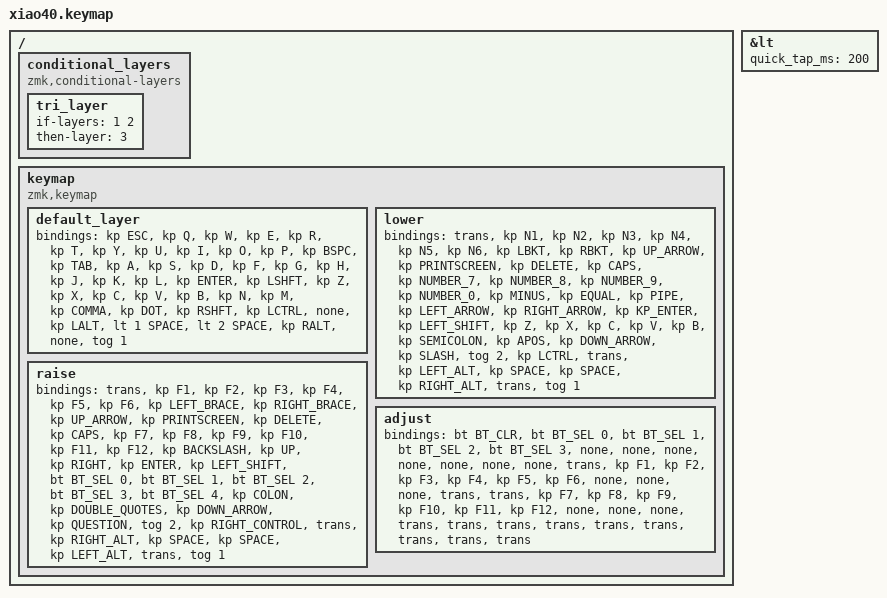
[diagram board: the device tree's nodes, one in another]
/*
 * Copyright (c) 2022 Ramon Imbao
 *
 * SPDX-License-Identifier: MIT
 */

#include <behaviors.dtsi>
#include <dt-bindings/zmk/keys.h>
#include <dt-bindings/zmk/bt.h>// Using layer taps on thumbs, having quick tap as well helps w/ repeating space/backspace
&lt {
    quick_tap_ms = <200>;
};

/ {
    conditional_layers {
        compatible = "zmk,conditional-layers";

        tri_layer {
            if-layers = <1 2>;
            then-layer = <3>;
        };
    };

    keymap {
        compatible = "zmk,keymap";

        default_layer {
            bindings = <
 &kp ESC   &kp Q   &kp W   &kp E   &kp R   &kp T   &kp Y   &kp U   &kp I   &kp O   &kp P  &kp BSPC  &kp TAB   &kp A   &kp S   &kp D   &kp F   &kp G   &kp H   &kp J   &kp K   &kp L  &kp ENTER  &kp LSHFT   &kp Z   &kp X   &kp C   &kp V   &kp B   &kp N   &kp M  &kp COMMA  &kp DOT  &kp RSHFT  &kp LCTRL   &none  &kp LALT  &lt 1 SPACE  &lt 2 SPACE  &kp RALT   &none  &tog 1
            >;
        };

        lower {
            bindings = <
 &trans  &kp N1  &kp N2  &kp N3  &kp N4  &kp N5  &kp N6  &kp LBKT  &kp RBKT  &kp UP_ARROW  &kp PRINTSCREEN  &kp DELETE  &kp CAPS  &kp NUMBER_7  &kp NUMBER_8  &kp NUMBER_9  &kp NUMBER_0  &kp MINUS  &kp EQUAL  &kp PIPE  &kp LEFT_ARROW  &kp RIGHT_ARROW  &kp KP_ENTER  &kp LEFT_SHIFT   &kp Z   &kp X   &kp C   &kp V   &kp B  &kp SEMICOLON  &kp APOS  &kp DOWN_ARROW  &kp SLASH  &tog 2  &kp LCTRL  &trans  &kp LEFT_ALT  &kp SPACE  &kp SPACE  &kp RIGHT_ALT  &trans  &tog 1
            >;
        };

        raise {
            bindings = <
 &trans  &kp F1  &kp F2  &kp F3  &kp F4  &kp F5  &kp F6  &kp LEFT_BRACE  &kp RIGHT_BRACE  &kp UP_ARROW  &kp PRINTSCREEN  &kp DELETE  &kp CAPS  &kp F7  &kp F8  &kp F9  &kp F10  &kp F11  &kp F12  &kp BACKSLASH  &kp UP  &kp RIGHT  &kp ENTER  &kp LEFT_SHIFT  &bt BT_SEL 0  &bt BT_SEL 1  &bt BT_SEL 2  &bt BT_SEL 3  &bt BT_SEL 4  &kp COLON  &kp DOUBLE_QUOTES  &kp DOWN_ARROW  &kp QUESTION  &tog 2  &kp RIGHT_CONTROL  &trans  &kp RIGHT_ALT  &kp SPACE  &kp SPACE  &kp LEFT_ALT  &trans  &tog 1
            >;
        };

        adjust {
            bindings = <
 &bt BT_CLR  &bt BT_SEL 0  &bt BT_SEL 1  &bt BT_SEL 2  &bt BT_SEL 3   &none   &none   &none   &none   &none   &none   &none  &trans  &kp F1  &kp F2  &kp F3  &kp F4  &kp F5  &kp F6   &none   &none   &none  &trans  &trans  &kp F7  &kp F8  &kp F9  &kp F10  &kp F11  &kp F12   &none   &none   &none  &trans  &trans  &trans  &trans  &trans  &trans  &trans  &trans  &trans
            >;
        };
    };
};
